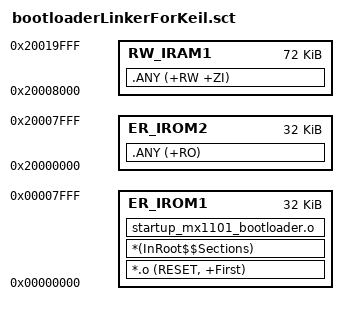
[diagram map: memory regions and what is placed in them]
; *************************************************************
; *** Scatter-Loading Description File generated by uVision ***
; *************************************************************

LR_IROM1 0x00000000 0x00008000 {
ER_IROM1 0x00000000 0x00008000
{                                                            
	*.o (RESET, +First)                                    
	*(InRoot$$Sections)
	startup_mx1101_bootloader.o
     }
ER_IROM2 0x20000000 0x00008000 { 
    .ANY (+RO)                                          
}
RW_IRAM1 0x20008000 0x00012000 
{  
   .ANY (+RW +ZI)
}
}

